# AE822FA0E5597BS0_CM55_HE_View register map
Vendor: Alif Semiconductor; Series: E8; File version: 1.0
CPU: CM55 r1p0, selectable endian, MPU, FPU, double-precision FPU, DSP, VTOR, 8 interrupt priority bits, 1 SAU regions
Registers are 32-bit, read-write, reset 0x0 unless marked. A register's access mark holds for its fields unless they carry their own. Offsets are from the block's base; [hi:lo] are bit positions; lines under a group give offsets from that group; {n}, {i} and the like mark numbered series; 'fields as' and 'values as' point back to an identical list.

## USB (part 2 of 2)
Base 0x48200000
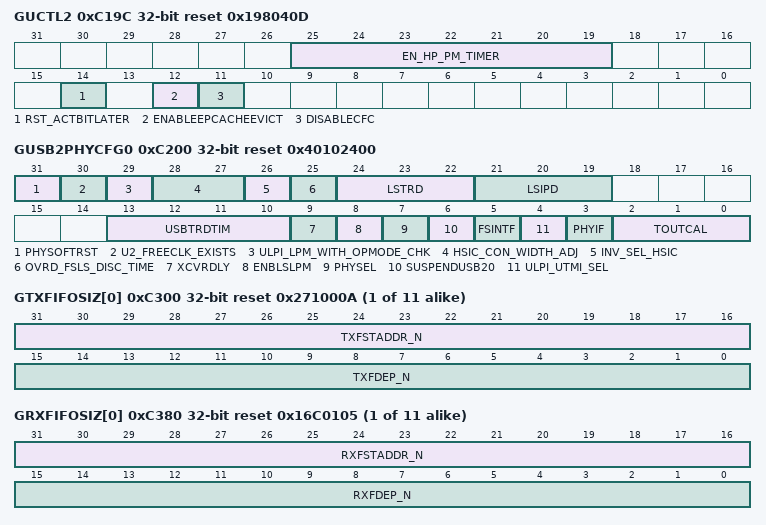
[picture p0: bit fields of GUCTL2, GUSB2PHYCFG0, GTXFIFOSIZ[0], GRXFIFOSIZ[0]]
0xC19C GUCTL2 reset 0x198040D — Global User Control Register 2
  [25:19] EN_HP_PM_TIMER — This register field is used to set new HP and PM timers. To enable PM timer, set the GUCTL2[19] bit as 0x1. To enable HP timer, set the GUCTL2[20] bit as 0x1. Default value of HP timer is 4 us when HP PM timer is not enabled; when new HP timer is enabled default value is 12 us.
  [14] RST_ACTBITLATER — Enable clearing of the command active bit for the ENDXFER command after the command execution is completed. This bit is valid in Device mode only.
  [12] ENABLEEPCACHEEVICT — Enable evicting endpoint cache after flow control for bulk endpoints. A performance enhancement was done to keep the non-stream capable bulk IN endpoint in cache after flow control. Setting this bit will disable this enhancement. This should be set only for debug purpose.
  [11] DISABLECFC — Disable xHCI Errata feature contiguous frame ID capability. This field controls the xHCI Errata feature Contiguous FrameID capability. When set, the HCCPARAMS1[CFC] bit will be set to 0x0 indicating that CFC is not supported. Disable this feature only if the application cannot tolerate Misssed Service Error events for ISOC transfers, and the system latencies are large to cause Missed Service errors even if the software is following the Isochronous Thresholding rules.
0xC200 GUSB2PHYCFG0 reset 0x40102400 — Global USB2 PHY Configuration Register
  [31] PHYSOFTRST — UTMI PHY soft reset. Causes the USB2PHY_RESET signal to be asserted to reset a UTMI PHY.
  [30] U2_FREECLK_EXISTS — U2 Free Clock Exists. This bit specifies whether USB 2.0 PHY provides a free-running PHY clock, which is active when the clock control input is active.
    0=USB 2.0 free clock does not exist; 1=USB 2.0 free clock exists
  [29] ULPI_LPM_WITH_OPMODE_CHK — Reserved. Keep at 0x0.
  [28:27] HSIC_CON_WIDTH_ADJ ro — Reserved.
  [26] INV_SEL_HSIC ro — Reserved.
  [25] OVRD_FSLS_DISC_TIME — Overriding the FS/LS disconnect time to 32 us. If this value is 0x0, the FS/LS disconnect time is set to 2.5 us as per the USB specification. If this value is non-zero, the disconnect detection time is set to 32 us.
  [24:22] LSTRD — LS turnaround time. This bit field indicates the value of the Rx-to-Tx packet gap for LS devices. The encoding is as follows: Note: This field is applicable only in Host mode. For normal operation (to work with most LS devices), set the default value of this bit field to 0x0 (2 bit times). The programmable LS device inter-packet gap and turnaround delays are provided to support some legacy LS devices that might require different delays than the default/fixed ones. Include PHY delays when programming the LSIPD/LSTRD values. For example, if PHY's TXENDDELAY in LS mode is 30 UTMI CLKs, then subtract this delay (~1 LS bit time) from the device delay requirement.
    0=2 bit times; 1=2.5 bit times; 2=3 bit times; 3=3.5 bit times; 4=4 bit times; 5=4.5 bit times; 6=5 bit times; 7=5.5 bit times
  [21:19] LSIPD — LS inter-packet time. This field indicates the value of Tx-to-Tx packet gap for LS devices. The encoding is as follows: Note: This field is applicable only in Host mode. For normal operation (to work with most LS devices), set the default value of this field to 0x2 (3 bit times). The programmable LS device inter-packet gap and turnaround delays are provided to support some legacy LS devices that might require different delays than the default/fixed ones. Include PHY delays when programming the LSIPD/LSTRD values.
    values as LSTRD
  [13:10] USBTRDTIM — USB 2.0 turnaround time. This bit field sets the turnaround time in PHY clocks. Specifies the response time for a MAC request to the Packet FIFO Controller (PFC) to fetch data from the DFIFO (SPRAM). The following are the required values for the minimum SoC bus frequency of 60 MHz. USB turnaround time is a critical certification criteria when using long cables and five hub levels. The required values for this field: Note: This field is valid only in Device mode.
    5=When the MAC interface is 16-bit UTMI+; 9=When the MAC interface is 8-bit UTMI+/ULPI
  [9] XCVRDLY — Transceiver Delay. Enables a delay between the assertion of the UTMI Transceiver Select signal (for HS) and the assertion of the TxValid signal during a HS Chirp. When this bit is set to 0x1, a delay (of approximately 2.5 us) is introduced from the time when the Transceiver Select is set to 0x0 (HS) to the time the TxValid is driven to 0 for sending the chirp-K. This bit is valid only in device mode.
  [8] ENBLSLPM — Enable UTMI_SLEEP_n and UTMI_L1_SUSPEND_n. The application uses this bit to control UTMI_SLEEP_n and UTMI_L1_SUSPEND_n assertion to the PHY in the L1 state. Note: This bit must be set to 0x1. Note: In Device mode, before issuing any device endpoint command, disable this bit and enable it after the command completes. Without disabling this bit, if a command is issued when the device is in L1 state and if MAC2_CLK (UTMI_CLK) is gated off, the command will not get completed.
    0=UTMI_SLEEP_n and UTMI_L1_SUSPEND_n assertion from the controller is not transferred to the PHY; 1=UTMI_SLEEP_n and UTMI_L1_SUSPEND_n assertion from the controller is transferred to the PHY
  [7] PHYSEL wo — USB 2.0 High-Speed PHY or USB 1.1 Full-Speed serial transceiver select. Note: USB 1.1 full-serial transceiver is not supported. This bit always reads as 0x0.
  [6] SUSPENDUSB20 — Suspend USB2.0 HS/FS/LS PHY. When this bit is set, USB2.0 PHY enters Suspend mode if Suspend conditions are valid. Application needs to set it to 0x1 after the controller initialization completes. Note: In Host mode, on reset, this bit is set to 0x1. Software can override this bit after reset. In Device mode, before issuing any device endpoint command, disable this bit and enable it after the command completes. If the user issues a command without disabling this bit when the device is in L2 state and if MAC2_CLK (UTMI_CLK/ULPI_CLK) is gated off, the command will not get completed.
  [5] FSINTF ro — Full-Speed serial interface select. Note: USB 1.1 full-speed serial interface is not supported. This bit always reads as 0x0.
  [4] ULPI_UTMI_SEL ro — ULPI or UTMI+ selection.
    0=UTMI+ interface; 1=ULPI interface
  [3] PHYIF — PHY interface. If UTMI+ is selected, the application uses this bit to configure the controller to support a UTMI+ PHY with an 8- or 16-bit interface.
    0=8 bits; 1=16 bits
  [2:0] TOUTCAL — HS/FS timeout calibration. The number of PHY clocks, as indicated by the application in this bit field, is multiplied by a bit-time factor; this factor is added to the High-Speed/Full-Speed interpacket timeout duration in the controller to account for additional delays introduced by the PHY. This may be required, since the delay introduced by the PHY in generating the LineState condition may vary among PHYs. The USB standard timeout value for high-speed operation is 736 to 816 (inclusive) bit times. The USB standard timeout value for Full-Speed operation is 16 to 18 (inclusive) bit times. The application must program this field based on the speed of connection. The number of bit times added per PHY clock are: High-Speed operation: - One 30-MHz PHY clock = 16 bit times - One 60-MHz PHY clock = 8 bit times Full-Speed operation: - One 30-MHz PHY clock = 0.4 bit times - One 60-MHz PHY clock = 0.2 bit times - One 48-MHz PHY clock = 0.25 bit times
{0xC300+4i} GTXFIFOSIZ[{i}] (i=0..10) reset 0x271000A — Global Transmit FIFO Size Register n
  [31:16] TXFSTADDR_N — Transmit FIFOn RAM start address. This bit field contains the memory start address for TxFIFOn in MDWIDTH-bit words.
  [15:0] TXFDEP_N — TxFIFO Depth. This field contains the depth of TxFIFOn in MDWIDTH-bit words.
{0xC380+4i} GRXFIFOSIZ[{i}] (i=0..10) reset 0x16C0105 — Global Receive FIFO Size Register n
  [31:16] RXFSTADDR_N — RxFIFOn RAM start address. This bit field contains the memory start address for RxFIFO n in MDWIDTH-bit words.
  [15:0] RXFDEP_N — RxFIFO depth. This bit field contains the depth of RxFIFO n in MDWIDTH-bit words.
0xC400 GEVNTADRLO0 — Global Event Buffer Address (Low)
  [31:0] EVNTADRLO — Event buffer address. This bit field holds the lower 32 bits of start address of the external memory for the Event Buffer. During operation, hardware does not update this address.
0xC404 GEVNTADRHI0 — Global Event Buffer Address (High)
  [31:0] EVNTADRHI — Event buffer address. This bit field holds the higher 32 bits of start address of the external memory for the Event Buffer. During operation, hardware does not update this address.
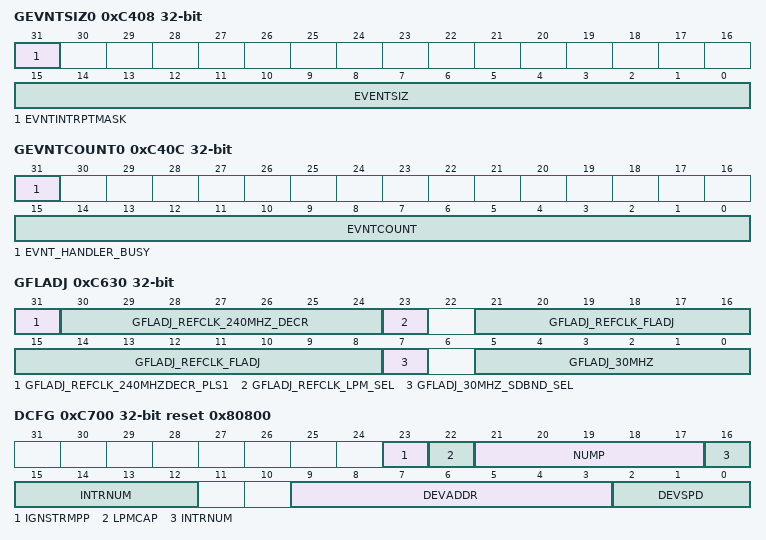
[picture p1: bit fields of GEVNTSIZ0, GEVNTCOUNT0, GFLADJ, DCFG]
0xC408 GEVNTSIZ0 — Global Event Buffer Size Register
  [31] EVNTINTRPTMASK — Event interrupt mask. When this bit is set to 0x1, this prevents the interrupt from being generated. However, even when the mask is set, the events are queued.
  [15:0] EVENTSIZ — Event buffer size in bytes. This bit field holds the size of the Event Buffer in bytes; must be a multiple of four. This is programmed by software once during initialization. The minimum size of the event buffer is 32 bytes.
0xC40C GEVNTCOUNT0 — Global Event Buffer Count Register
  [31] EVNT_HANDLER_BUSY — Event handler busy. Device software event handler busy indication. The controller sets this bit when the interrupt line is asserted due to pending events. Software clears this bit (with 0x1) when it has finished processing the events (along with updating the EVNTCOUNT bit field in this register). The controller does not raise the interrupt line for a new event unless this bit is cleared. Note: When interrupt moderation is disabled (that is, the DEV_IMOD0[DEVICE_IMODI] = 0x0), this bit is ignored.
  [15:0] EVNTCOUNT — Event count. When read, returns the number of valid events in the Event Buffer (in bytes). When written, hardware decrements the count by the value written. When interrupt moderation is enabled (that is, the DEV_IMOD0[DEVICE_IMODI] != 0x0), the interrupt line gets de-asserted when the first write happens on this register to decrement the count. When interrupt moderation is disabled (that is, the DEV_IMOD0[DEVICE_IMODI] = 0x0), the interrupt line continues to get asserted until the event count becomes zero (no-moderation behavior).
0xC600 GHWPARAMS8 ro reset 0x43C — Global Hardware Parameters Register 8
  [31:0] GHWPARAMS8_32_0 — Default RAM0 cache depth.
0xC610 GTXFIFOPRIDEV — Global Device TX FIFO DMA Priority Register
  [3:0] GTXFIFOPRIDEV — Device TxFIFO priority.
0xC618 GTXFIFOPRIHST — Global Host TX FIFO DMA Priority Register
  [2:0] GTXFIFOPRIHST — Host TxFIFO priority.
0xC61C GRXFIFOPRIHST — Global Host RX FIFO DMA Priority Register
  [2:0] GRXFIFOPRIHST — Host RxFIFO priority.
0xC630 GFLADJ — Global Frame Length Adjustment Register
  [31] GFLADJ_REFCLK_240MHZDECR_PLS1 — This bit indicates that the decrement value that the controller applies for each REF_CLK must be GFLADJ_REFCLK_240MHZ_DECR and GFLADJ_REFCLK_240MHZ_DECR + 1 alternatively on each REF_CLK. Set this bit to a 0x1 only if the GFLADJ_REFCLK_LPM_SEL bit is set to 0x0 and the fractional component of 240/REF_CLK_FREQUENCY is greater than or equal to 0.5. Examples: If the REF_CLK is 19.2 MHz then: - GUCTL[REF_CLK_PERIOD] = 52 - GFLADJ[GFLADJ_REFCLK_240MHZ_DECR] = (240/19.2) = 12.5 - GFLADJ[GFLADJ_REFCLK_240MHZDECR_PLS1] = 1 - GUCTL[REF_CLK_PERIOD] = 41 - GFLADJ[GFLADJ_REFCLK_240MHZ_DECR] = (240/24) = 10 - GFLADJ[GFLADJ_REFCLK_240MHZDECR_PLS1] = 0
  [30:24] GFLADJ_REFCLK_240MHZ_DECR — This bit field indicates the decrement value that the controller applies for each REF_CLK in order to derive a frame timer in terms of a 240-MHz clock. This field must be programmed to a non-zero value only if GFLADJ_REFCLK_LPM_SEL is set to 0x1. The value is derived as follows: GFLADJ_REFCLK_240MHZ_DECR = 240/REF_CLK_FREQUENCY Examples: If the REF_CLK is 24 MHz then: - GUCTL[REF_CLK_PERIOD] = 41 - GFLADJ[GFLADJ_REFCLK_240MHZ_DECR] = 240/24 = 10 - GUCTL[REF_CLK_PERIOD] = 20 - GFLADJ[GFLADJ_REFCLK_240MHZ_DECR] = 240/48 = 5 - GUCTL[REF_CLK_PERIOD] = 58 - GFLADJ[GFLADJ_REFCLK_240MHZ_DECR] = 240/17 = 14
  [23] GFLADJ_REFCLK_LPM_SEL — This bit enables the functionality of running SOF/ITP counters on the REF_CLK. In Device mode, setting this bit to 0x1 enables SOF tracking using REF_CLK. Note that the REF_CLK frequencies supported in this mode are 16/17/19.2/20/24/39.7/40 MHz. Note: If this bit is set to 0x1, the GUSB2PHYCFG0[U2_FREECLK_EXISTS] bit must be set to 0x0.
  [21:8] GFLADJ_REFCLK_FLADJ — This bit field indicates the frame length adjustment to be applied when SOF/ITP counter is running on the REF_CLK. The GFLADJ_REFCLK_FLADJ value is used to adjust the ITP interval when the GCTL[SOFITPSYNC] bit is set to 0x1; SOF and ITP interval when the GFLADJ_REFCLK_LPM_SEL bit is set to 0x1. This field must be programmed to a non-zero value only if GFLADJ_REFCLK_LPM_SEL bit is set to 0x1. The value is derived as follows: FLADJ_REF_CLK_FLADJ = ((125000/REF_CLK_PERIOD_INTEGER) - (125000/REF_CLK_PERIOD)) x REF_CLK_PERIOD, where: 1) The REF_CLK_PERIOD_INTEGER is the integer value of the REF_CLK period got by truncating the decimal (fractional) value that is programmed in the GUCTL[REF_CLK_PERIOD] bit field. 2) The REF_CLK_PERIOD is the REF_CLK period including the fractional value. - GUCTL[REF_CLK_PERIOD] = 41 - GFLADJ[GLADJ_REFCLK_FLADJ] = ((125000/41) - (125000/41.6666)) x 41.6666 = 2032 (ignoring the fractional value) - GUCTL[REF_CLK_PERIOD] = 20 - GFLADJ[GLADJ_REFCLK_FLADJ] = ((125000/20) - (125000/20.8333)) x 20.8333 = 5208 (ignoring the fractional value)
  [7] GFLADJ_30MHZ_SDBND_SEL — This field selects whether to use the FLADJ_30MHZ_REG input signal or the GFLADJ[GFLADJ_30MHZ] to adjust the frame length for the SOF/ITP. When this bit is set to:
    0=The controller uses the FLADJ_30MHZ_REG input signal value; 1=The controller uses the register field GFLADJ[GFLADJ_30MHZ] value
  [5:0] GFLADJ_30MHZ — This bit field indicates the value that is used for frame length adjustment instead of considering from the sideband input signal FLADJ_30MHZ_REG. For details on how to set this value, refer to section , 'Frame Length Adjustment Register (FLADJ),' of the xHCI Specification.
0xC640 GUSB2RHBCTL0 — Global USB 2.0 Root Hub Control Register
  [3:0] OVRD_L1TIMEOUT — Overriding the driver programmed L1TIMEOUT value. If this bit is set to 0x0, the L1 Timeout value is taken from the xHCI PORTHLPMC register. If this value is non-zero, then this will override the L1 Timeout value programmed in the xHCI PORTHLPMC register. In that case the actual L1 Timeout would be 2^(OVRD_L1TIMEOUT-1) x 8 us (1 = 8 us, 2 = 16 us, 3 = 32 us and so forth).
0xC700 DCFG reset 0x80800 — Device Configuration Register
  [23] IGNSTRMPP — Ignore Stream PP. This bit only affects stream-capable bulk endpoints. When this bit is set to 0x0 and the controller receives a Data Packet with the Packet Pending (PP) bit set to 0x0 for OUT endpoints, or it receives an ACK with the NUMP bit field set to 0x0 and PP set to 0x0 for IN endpoints, the controller attempts to search for another stream (CStream) to initiate to the host. However, there are two situations where this behavior is not optimal: When the host is setting PP = 0 even though it has not finished the stream, or when the endpoint on the device is configured with one transfer resource and therefore does not have any other streams to initiate to the host.
  [22] LPMCAP — LPM Capable. The application uses this bit to control the LPM capabilities of the controller. If the controller operates as a non-LPM-capable device, it cannot respond to LPM transactions.
    0=LPM capability is not enabled; 1=LPM capability is enabled
  [21:17] NUMP — Number of Receive Buffers. This bit field indicates the number of receive buffers to be reported in the ACK TP. For an OUT endpoint, this bit field controls the number of receive buffers reported in the NUMP bit field of the ACK TP transmitted by the controller. Note: This bit is used in host mode when Debug Capability is enabled.
  [16:12] INTRNUM — Interrupt number Indicates interrupt/EventQ number on which non-endpoint-specific device-related interrupts (see Section Event Buffer Content for Device-Specific Events (DEVT)) are generated.
  [9:3] DEVADDR — Device Address. The application must perform the following: - Program this field after every SetAddress request. - Reset this field to zero after USB reset.
  [2:0] DEVSPD — Device Speed. Indicates the speed at which the application requires the controller to connect, or the maximum speed the application can support. However, the actual bus speed is determined only after the chirp sequence is completed, and is based on the speed of the USB host to which the controller is connected.
    0=High-speed (USB 2.0 PHY clock is 30 MHz or 60 MHz); 1=Full-speed (USB 2.0 PHY clock is 30 MHz or 60 MHz); 4=SuperSpeed (USB 3.0 PHY clock is 125 MHz or 250 MHz)
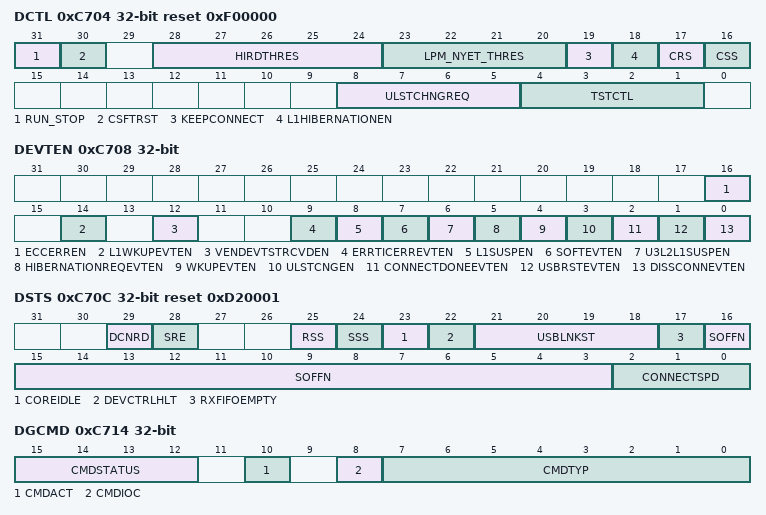
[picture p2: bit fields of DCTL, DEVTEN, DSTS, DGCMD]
0xC704 DCTL reset 0xF00000 — Device Control Register
  [31] RUN_STOP — Run/Stop. The software writes 0x1 to this bit to start the device controller operation. To stop the device controller operation, the software must remove any active transfers and write 0x0 to this bit. When the controller is stopped, it sets the DSTS[DEVCTRLHLT] bit when the controller is idle and the lower layer finishes the disconnect process. This bit must be used in following cases as specified: - After power-on reset and CSR initialization, the software must write 0x1 to this bit to start the device controller. The controller does not signal connect to the host until this bit is set. - The software uses this bit to control the device controller to perform a soft disconnect. When the software writes 0x0 to this bit, the host does not see that the device is connected. The device controller stays in the disconnected state until the software writes 0x1 to this bit. The minimum duration of keeping this bit cleared is specified in the Note below. If the software attempts a connect after the soft disconnect or detects a disconnect event, it must set the ULSTCHNGREQ bit field to 0x5 before reasserting the RUN_STOP bit. - When the USB or Link is in a lower power state and the Two Power Rails configuration is selected, software writes 0x0 to this bit to indicate that it is going to turn off the Core Power Rail. After the software turns on the Core Power Rail again and re-initializes the device controller, it must set this bit to start the device controller. For more details, see Section Low Power Operation of Controller. Note: The following is the minimum duration for which the soft disconnect (SftDiscon) bit must be set for the USB host to detect a device disconnect. 10 ms: 1) For high-speed, when the device state is Suspended, Idle, or not Idle/Suspended (performing transactions). 2) For full-speed/low-speed, when the device state is Suspended, Idle, or not Idle/Supended (performing transactions).
  [30] CSFTRST write-1-sets — Core Soft Reset. Resets the all clock domains as follows: This bit clears the interrupts and all the CSRs except the GSTS, GSNPSID, GUID, GUSB2PHYCFG0, DCFG, DCTL, DEVTEN, and DSTS registers. All module state machines (except the SoC Bus Slave Unit) are reset to the IDLE state, and all the TxFIFOs and the RxFIFO are flushed. Any transactions on the SoC bus Master are terminated as soon as possible, after gracefully completing the last data phase of a SoC bus transfer. Any transactions on the USB are terminated immediately. Note: Programming this field with random data causes side effect. Bit Bash register testing is not recommended.
  [28:24] HIRDTHRES — HIRD Threshold (HIRD_Thres). The controller asserts output signals utmi_l1_suspend_n and utmi_sleep_n on the basis of this signal. The controller asserts utmi_l1_suspend_n to put the PHY into Deep Low-Power mode in L1 when both of the following are true: - HIRD value is greater than or equal to the value of bits 3-1 in the DCTL[HIRDTHRES] bit field and the value of bit 4 in the DCTL[HIRDTHRES] is set to 0x1. The controller asserts utmi_sleep_n on L1 when one of the following is true: - If the HIRD value is less than the value of bits 3-1 in the DCTL[HIRDTHRES] bit field or the value of bit 4 in the DCTL[HIRDTHRES] is set to 0x0.
  [23:20] LPM_NYET_THRES — LPM NYET Threshold. When LPM Errata is enabled: Handshake response to LPM token specified by device application. Response depends on the DCFG[LPMCAP] bit. 1) DCFG[LPMCAP] bit is 0x0: the controller always responds with Timeout (that is, no response). 2) DCFG[LPMCAP] bit is 0x1: the controller responds with an ACK on successful LPM transaction, which requires that all of the following are satisfied: - There are no PID or CRC5 errors in both the EXT token and the LPM token (if not true, inactivity results in a timeout ERROR). - No data is pending in the TxFIFO and RxFIFO is empty (else NYET). - The BESL value in the LPM token is less than or equal to the LPM_NYET_THRES bit field.
  [19] KEEPCONNECT — Keep Connect. Note: If Hibernation is disabled, that is, GCTL[GBLHIBERNATIONEN] = 0x0, this bit is tied to zero.
  [18] L1HIBERNATIONEN — L1 Hibernation Enable. Note: If Hibernation is disabled, that is, GCTL[GBLHIBERNATIONEN] = 0x0, this bit is tied to zero.
  [17] CRS — Controller Restore State (CRS). This command is similar to the USBCMD[CRS] bit in Host mode and initiates the restore process. When software sets this bit to 0x1, the controller immediately sets the DSTS[RSS] bit to 0x1. When the controller has finished the restore process, it sets the DSTS[RSS] bit to 0x0. Note: When read, this field always returns 0x0.
  [16] CSS — Controller Save State (CSS). This command is similar to the USBCMD[CSS] bit in host mode and initiates the save process. When software sets this bit to 0x3, the controller immediately sets the DSTS[SSS] bit to 0x1. When the controller has finished the save process, it sets the DSTS[SSS] bit to 0x0. Note: When read, this field always returns 0x0.
  [8:5] ULSTCHNGREQ wo — USB/Link state change request. Software writes this bit field to issue a USB/Link state change request. A change in this bit field indicates a new request to the controller. If software wants to issue the same request back-to-back, it must write a 0x0 to this bit field between the two requests. The result of the state change request is reflected in the USB/Link State in the DSTS register. These bits are self-cleared on the MAC Layer exiting suspended state. If software is updating other fields of the DCTL register and not intending to force any link state change, then it must write a 0x0 to this field. If the user writes 0x2 to the USB/Link State Change field and 0x1 to RUN/STOP, the link goes to compliance mode. Once you are in compliance, you may alternately write zero and '10' to this field to advance the compliance pattern. ValueRequested USB state transition 8 Remote wakeup request Others: Reserved
  [4:1] TSTCTL — Test Control. Others: Reserved
    0=Test mode disabled; 1=Test_J mode; 2=Test_K mode; 3=Test_SE0_NAK mode; 4=Test_Packet mode; 5=Test_Force_Enable
0xC708 DEVTEN — Device Event Enable Register
  [16] ECCERREN ro — ECC Error Enable. If this bit is set to 0x1, the controller reports an ECC error to the software when an uncorrectable ECC occurs internally.
  [14] L1WKUPEVTEN — L1 Resume Detected Event Enable. Note: If the GUCTL1[DEV_DECOUPLE_L1L2_EVT] bit is enabled, then this bit is for L1 Resume Detected Event Enable.
  [12] VENDEVTSTRCVDEN — Vendor Device Test LMP Received Event
  [9] ERRTICERREVTEN — Erratic Error Event Enable.
  [8] L1SUSPEN — L1 Suspend Event Enable Note: Only if the GUCTL1[DEV_DECOUPLE_L1L2_EVT] bit is enabled, this bit is for L1 Suspend Event Enable.
  [7] SOFTEVTEN — Start of (micro)frame.
  [6] U3L2L1SUSPEN — L2 or L2L1 Suspend Event Enable. Note: 1) If the GUCTL1[DEV_DECOUPLE_L1L2_EVT] bit is enabled, then this bit is for L2 Suspend Event Enable. 2) If the GUCTL1[DEV_DECOUPLE_L1L2_EVT] bit is not enabled, then this bit is for L2L1 Suspend Event Enable.
  [5] HIBERNATIONREQEVTEN — This bit enables/disables the generation of the Hibernation Request Event.
  [4] WKUPEVTEN — L2 or L2L1 Resume Detected Event Enable. Note: 1) If the GUCTL1[DEV_DECOUPLE_L1L2_EVT] bit is enabled, then this bit is for L2 Resume Detected Event Enable. 2) If the GUCTL1[DEV_DECOUPLE_L1L2_EVT] bit is not enabled, then this bit is for L2L1 Resume Detected Event Enable.
  [3] ULSTCNGEN — USB/Link State Change Event Enable.
  [2] CONNECTDONEEVTEN — Connection Done Enable.
  [1] USBRSTEVTEN — USB Reset Enable.
  [0] DISSCONNEVTEN — Disconnect Detected Event Enable.
0xC70C DSTS reset 0xD20001 — Device Status Register
  [29] DCNRD ro — Device Controller Not Ready (not used).
  [28] SRE write-1-clears — Save Restore Error. Currently not supported.
  [25] RSS ro — RSS Restore State Status. This bit is similar to the USBSTS[RSS] bit in Host mode. When the controller finishes the restore process, it completes the command by setting the RSS bit to 0x0.
  [24] SSS ro — SSS Save State Status. This bit is similar to the USBSTS[SSS] in host mode. When the controller has finished the save process, it completes the command by setting the SSS bit to 0x0.
  [23] COREIDLE ro — Core Idle. The bit indicates that the controller finished transferring all RxFIFO data to system memory, writing out all completed descriptors, and all Event Counts are zero. Note: While testing for Reset values, mask out the read value. This bit represents the changing state of the controller and does not hold a static value.
  [22] DEVCTRLHLT ro — Device Controller Halted. This bit is set to 0x0 when the DCTL[RUN_STOP] bit is set to 0x1. The controller sets this bit to 0x1 when, after software sets the DCTL[RUN_STOP] bit to 0x0, the controller is idle and the lower layer finishes the disconnect process. When this bit is set to 0x1, the controller does not generate Device events. Note: The controller does not set this bit to 0x1 if the GEVNTCOUNT0 register has some valid value. Software needs to acknowledge the events that are generated (by writing to the GEVNTCOUNT0 register) while it is waiting for this bit to be set to 0x1. When Interrupt Moderation is enabled, there could be delay in raising the interrupt line when the event count is non-zero. Software should read the GEVNTCOUNT0 register directly and acknowledge them.
  [21:18] USBLNKST ro — USB/Link State. When Hibernation is enabled, the GCTL[GBLHIBERNATIONEN] = 0x1, the USBLNKST bit field is valid only when the DCTL[RUN_STOP] bit is set to 0x1 and the DCNRD = 0x0. The Early Suspend link state is an early indication of device suspend in HS/FS. The link state changes to Early Suspend after detecting bus idle for 3 ms. In HS operation, this is an indication that the USB bus (that is, LineState) has been in idle (SE0) for 3 ms. However, it does not confirm whether the next process is Suspend or Reset. The device checks the bus again after pull up enable delay and if the line state indicates Suspend (full speed J), then the device waits for an additional time (~3 ms) to indicate the actual Suspend state. In FS operation, this is an indication that the USB bus (that is, LineState) has been in idle (J) for 3 ms. The device waits for an additional time (~3 ms of Idle) to indicate the actual Suspend state.
    0=On state; 2=Sleep (L1) state; 3=Suspend (L2) state; 4=Disconnected state (Default state); 5=Early Suspend state (valid only when Hibernation is disabled, the GCTL[GBLHIBERNATIONEN] = 0x0); 14=Reset (valid only when Hibernation is enabled, the GCTL[GBLHIBERNATIONEN] = 0x1); 15=Resume (valid only when Hibernation is enabled, the GCTL[GBLHIBERNATIONEN] = 0x1)
  [17] RXFIFOEMPTY ro
  [16:3] SOFFN ro — Frame/Microframe Number of the Received SOF. Bits 16-14 are not used. Software can ignore these 3 bits. Bits 13-3 indicate the frame number. Note: After power-on reset, the controller generates the microframe number internally for every 125 us if the USB host has not issued SOF/ITP yet. During P3 state, the duration of SOFFN is based on the SUSPEND_CLK frequency.
  [2:0] CONNECTSPD ro — Connected Speed. Indicates the speed at which the USB controller has come up after speed detection through a chirp sequence.
    0=High-speed (PHY clock is running at 30 or 60 MHz); 1=Full-speed (PHY clock is running at 30 or 60 MHz); 4=SuperSpeed (PHY clock is running at 125 or 250 MHz)
0xC710 DGCMDPAR — Device Generic Command Parameter Register
  [31:0] PARAMETER
0xC714 DGCMD — Device Generic Command Register
  [15:12] CMDSTATUS ro — Command Status.
    0=Indicates command success; 1=Indicates that the device controller encountered an error while processing the command
  [10] CMDACT write-1-sets — Command Active. The software sets this bit to 0x1 to enable the device controller to execute the generic command. The device controller sets this bit to 0x0 after executing the command.
  [8] CMDIOC — Command Interrupt on Complete. When this bit is set, the device controller issues a Generic Command Completion event after executing the command. Note that this interrupt is mapped to the DCFG[INTRNUM] bit field. Note: This field must not set to 0x0 if the DCTL[RUN_STOP] bit is set to 0x0.
  [7:0] CMDTYP — Generic Command Type. Specifies the type of generic command the software driver is requesting the controller to perform.
    2=Set Periodic Parameters; 4=Set Scratchpad Buffer Array Address Lo; 5=Set Scratchpad Buffer Array Address Hi; 7=Transmit Device Notification; 9=Selected FIFO Flush; 10=All FIFO Flush; 12=Set Endpoint NRDY; 16=Run SoC Bus LoopBack Test; 17=Restart After Disconnect
0xC720 DALEPENA — Device Active USB Endpoint Enable Register
  [31:0] USBACTEP — USB Active Endpoints. This field indicates if a USB endpoint is active in the current configuration and interface. It applies to USB IN endpoints 0.15 and OUT endpoints 0.15, with one bit for each of the 32 possible endpoints. Even numbers are for USB OUT endpoints, and odd numbers are for USB IN endpoints, as follows: - Bit[0]: USB EP0-OUT - Bit[1]: USB EP0-IN - Bit[2]: USB EP1-OUT - Bit[3]: USB EP1-IN The entity programming this register must set bits 0x0 and 0x1 because they enable control endpoints that map to physical endpoints (resources) after USBReset. Hardware clears these bits for all endpoints (other than EP0-OUT and EP0-IN) after detecting a USB reset event. After receiving SetConfiguration and SetInterface requests, the application must program endpoint registers accordingly and set these bits.
{0xC800+0x10*i} USB_ENDPNT_CMD[{i}] (i=0..15) group
  0x00 DEPCMDPAR2 — Device Physical Endpoint-n Command Parameter 2 Register
    [31:0] PARAMETER
  0x04 DEPCMDPAR1 — Device Physical Endpoint-n Command Parameter 1 Register
    [31:0] PARAMETER
  0x08 DEPCMDPAR0 — Device Physical Endpoint-n Command Parameter 0 Register
    [31:0] PARAMETER
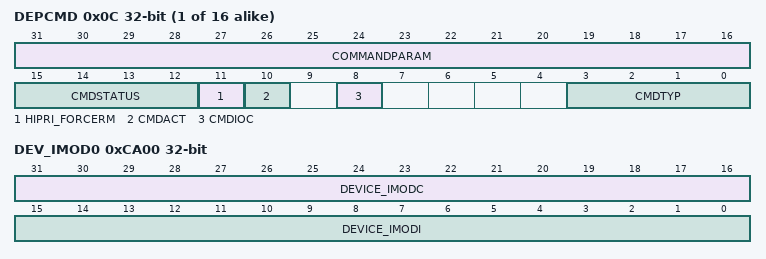
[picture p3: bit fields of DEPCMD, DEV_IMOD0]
  0x0C DEPCMD — Device Physical Endpoint-n Command Register
    [31:16] COMMANDPARAM — Command Parameters or Event Parameters. When this register is written: 1) For Start Transfer command: - Bits [31-16]: StreamID. The USB StreamID assigned to this transfer 2) For Start Transfer command applied to an isochronous endpoint: - Bits [31-16]: StartMicroFramNum: Indicates the (micro)frame number to which the first TRB applies. 3) For Update Transfer, End Transfer, and Start New Configuration commands: - Bits [22-16]: Transfer Resource Index (XferRscIdx). The hardware-assigned transfer resource index for the transfer, which was returned in response to the Start Transfer command. The application software-assigned transfer resource index for a Start New Configuration command.
    [15:12] CMDSTATUS — Command Completion Status. Additional information about the completion of this command is available in this bit field. The information is in the same format as bits 15-12 of the Endpoint Command Complete event, see Section Event Buffer Content for Device Endpoint-Specific Events (DEPEVT).
    [11] HIPRI_FORCERM — HighPriority/ForceRM HighPriority: Only valid for Start Transfer command ForceRM: Only valid for End Transfer command ClearPendIN: Only valid for Clear Stall command . Software sets this bit to clear any pending IN transaction (on that endpoint) stuck at the lower layers when a Clear Stall command is issued.
    [10] CMDACT — Command Active. Software sets this bit to 0x1 to enable the device endpoint controller to execute the generic command. The device controller sets this bit to 0x0 when the CMDSTATUS bit field is valid and the endpoint is ready to accept another command. This does not imply that all the effects of the previously-issued command have taken place.
    [8] CMDIOC — Command Interrupt on Complete. When this bit is set, the device controller issues a generic Endpoint Command Complete event after executing the command. Note that this interrupt is mapped to the INTRNUM bit field. When the DEPCFG command is executed, the command interrupt on completion goes to the interrupt pointed by the INTRNUM bit field in the current command. Note: This field must not be set to 0x1 if the DCTL[RUN_STOP] bit is 0x0.
    [3:0] CMDTYP — Command Type. Specifies the type of command the software driver is requesting the controller to perform.
      1=Set Endpoint Configuration: 64- or 96-bit Parameter; 2=Set Endpoint Transfer Resource Configuration: 32-bit Parameter; 3=Get Endpoint State: No Parameter Needed; 4=Set Stall: No Parameter Needed; 5=Clear Stall (see Set Stall): No Parameter Needed; 6=Start Transfer: 64-bit Parameter; 7=Update Transfer: No Parameter Needed; 8=End Transfer: No Parameter Needed; 9=Start New Configuration: No Parameter Needed
0xCA00 DEV_IMOD0 — Device Interrupt Moderation Register
  [31:16] DEVICE_IMODC — Interrupt Moderation Down Counter. Loaded with the DEVICE_IMODI value, whenever the hardware interrupt(n) line is de-asserted from the asserted state, counts down to 0, and stops. The interrupt is signaled whenever this counter is 0, the GEVNTCOUNT0[EVNT_HANDLER_BUSY] bit is 0x0, and there are pending events (that is, event count is non-zero). This counter may be directly written by software at any time to alter the interrupt rate.
  [15:0] DEVICE_IMODI — Moderation Interval. This bit field holds the minimum inter-interrupt interval between events. The interval is specified in terms of 250-ns increments. A value of 0 disables the interrupt throttling logic and interrupts are generated immediately if event count becomes non-zero. In scaledown simulation mode, 4 RAM clocks are used to time 250 ns.
